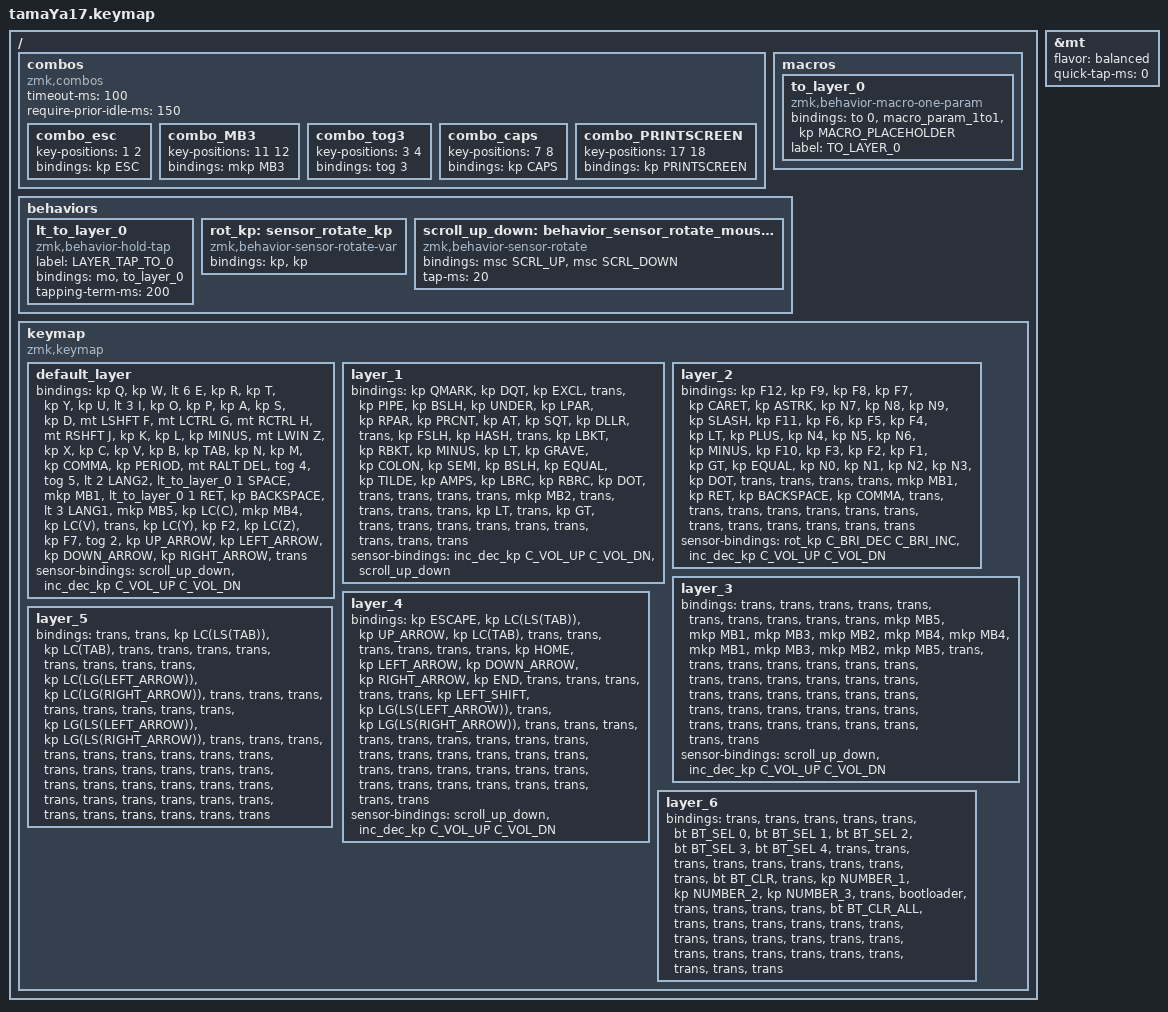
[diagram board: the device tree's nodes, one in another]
#include <behaviors.dtsi>
#include <dt-bindings/zmk/bt.h>
#include <dt-bindings/zmk/keys.h>
#include <dt-bindings/zmk/pointing.h>
#include <dt-bindings/zmk/mouse.h>
#include <behaviors/rgbled_widget.dtsi>  // led制御

#define ZMK_POINTING_DEFAULT_SCRL_VAL 100

#define MOUSE 3

&mt {
    flavor = "balanced";
    quick-tap-ms = <0>;
};

/ {
    // 複数キーの同時押しに特別の入力を設定できる
    // キー番号早見表：
    //  0  1  2  3  4         5  6  7  8  9
    // 10 11 12 13 14        15 16 17 18 19
    // 20 21 22 23 24        25 26 27 28 29
    

    combos {
        compatible = "zmk,combos";
        timeout-ms = <100>;
        require-prior-idle-ms = <150>;

        combo_esc {
            key-positions = <1 2>;
            bindings = <&kp  ESC>;
        };

        combo_MB3 {
            key-positions = <11 12>;
            bindings = <&mkp MB3>;
         };
    
        combo_tog3 {
            key-positions = <3 4>;
            bindings = <&tog 3>;
        };

        combo_caps {
            key-positions = <7 8>;
            bindings = <&kp CAPS>;
        };

        combo_PRINTSCREEN {
            key-positions = <17 18>;
            bindings = <&kp PRINTSCREEN>;
        };
       

    };

    //マクロ(既存のキーの組み合わせ)
    macros {
        to_layer_0: to_layer_0 {
            compatible = "zmk,behavior-macro-one-param";
            #binding-cells = <1>;
            bindings = <&to 0 &macro_param_1to1 &kp MACRO_PLACEHOLDER>;
            label = "TO_LAYER_0";
        };
    };

    //新たな動作を定義する
    behaviors {
        lt_to_layer_0: lt_to_layer_0 {
            compatible = "zmk,behavior-hold-tap";
            label = "LAYER_TAP_TO_0";
            bindings = <&mo>, <&to_layer_0>;

            #binding-cells = <2>;
            tapping-term-ms = <200>;
        };

        rot_kp: sensor_rotate_kp {
            compatible = "zmk,behavior-sensor-rotate-var";
            #sensor-binding-cells = <2>;
            bindings = <&kp>, <&kp>;
        };


        scroll_up_down: behavior_sensor_rotate_mouse_wheel_up_down {
            compatible = "zmk,behavior-sensor-rotate";
            #sensor-binding-cells = <0>;
            bindings = <&msc SCRL_UP>, <&msc SCRL_DOWN>;

            tap-ms = <20>;
        };

    };

    //キーマップ設定
    keymap {
        compatible = "zmk,keymap";

        default_layer { //デフォルトレイヤー(レイヤー0)
            bindings = <
            &kp Q       &kp W      &lt 6 E      &kp R         &kp T                                                      &kp Y           &kp U          &lt 3 I         &kp O           &kp P
            &kp A       &kp S      &kp D        &mt LSHFT F   &mt LCTRL G                                                &mt RCTRL H     &mt RSHFT J    &kp K           &kp L           &kp MINUS
            &mt LWIN Z  &kp X      &kp C        &kp V         &kp B                                &kp TAB               &kp N           &kp M          &kp COMMA       &kp PERIOD      &mt RALT DEL
                        &tog 4     &tog 5       &lt 2 LANG2   &lt_to_layer_0 1 SPACE  &mkp MB1     &lt_to_layer_0 1 RET  &kp BACKSPACE   &lt 3 LANG1                                
            &mkp MB5    &kp LC(C)  &mkp MB4     &kp LC(V)     &trans                                                     &kp LC(Y)       &kp F2         &kp LC(Z)       &kp F7          &tog 2
                                                                                                                         &kp UP_ARROW  &kp LEFT_ARROW   &kp DOWN_ARROW  &kp RIGHT_ARROW &trans
            >;

            sensor-bindings = 
                <&scroll_up_down>,
                <&inc_dec_kp C_VOL_UP C_VOL_DN>;
        };

        layer_1 {   //レイヤー1の時の設定
            bindings = <
            &kp QMARK  &kp DQT   &kp EXCL  &trans   &kp PIPE                           &kp BSLH  &kp UNDER  &kp LPAR  &kp RPAR  &kp PRCNT
            &kp AT     &kp SQT   &kp DLLR  &trans   &kp FSLH                           &kp HASH  &trans     &kp LBKT  &kp RBKT  &kp MINUS
            &kp LT     &kp GRAVE &kp COLON &kp SEMI &kp BSLH                &kp EQUAL  &kp TILDE &kp AMPS   &kp LBRC  &kp RBRC  &kp DOT
                       &trans    &trans    &trans   &trans    &mkp MB2      &trans     &trans    &trans
            &trans     &kp LT    &trans    &kp GT                                      &trans    &trans     &trans    &trans    &trans    
                                                                                       &trans    &trans     &trans    &trans
            >;

            sensor-bindings =
                <&inc_dec_kp C_VOL_UP C_VOL_DN>,
                <&scroll_up_down>;
        };

        layer_2 {   //レイヤー2の時の設定
            bindings = <
            &kp F12  &kp F9  &kp F8  &kp F7  &kp CARET                       &kp ASTRK     &kp N7  &kp N8  &kp N9  &kp SLASH
            &kp F11  &kp F6  &kp F5  &kp F4  &kp LT                          &kp PLUS      &kp N4  &kp N5  &kp N6  &kp MINUS
            &kp F10  &kp F3  &kp F2  &kp F1  &kp GT               &kp EQUAL  &kp N0        &kp N1  &kp N2  &kp N3  &kp DOT
                     &trans  &trans  &trans  &trans    &mkp MB1   &kp RET    &kp BACKSPACE &kp COMMA
            &trans   &trans  &trans  &trans                                  &trans        &trans  &trans  &trans  &trans    
                                                                             &trans        &trans  &trans  &trans
            >;

            sensor-bindings =
                <&rot_kp C_BRI_DEC C_BRI_INC>,
                <&inc_dec_kp C_VOL_UP C_VOL_DN>;
        };

        layer_3 {     //レイヤー3の時の設定(マウスレイヤー)
            bindings = <
            &trans    &trans    &trans    &trans    &trans                      &trans    &trans    &trans    &trans    &trans
            &mkp MB5  &mkp MB1  &mkp MB3  &mkp MB2  &mkp MB4                    &mkp MB4  &mkp MB1  &mkp MB3  &mkp MB2  &mkp MB5
            &trans    &trans    &trans    &trans    &trans              &trans  &trans    &trans    &trans    &trans    &trans
                      &trans    &trans    &trans    &trans    &trans    &trans  &trans    &trans
            &trans    &trans    &trans    &trans    &trans                      &trans    &trans    &trans    &trans    &trans
                                                                                &trans    &trans    &trans    &trans    
            >;

           sensor-bindings =
                <&scroll_up_down>,
                <&inc_dec_kp C_VOL_UP C_VOL_DN>;
            
        };


        layer_4 {    //レイヤー4の時の設定(DAWレイヤー)
            bindings = <
            &kp ESCAPE      &kp LC(LS(TAB))         &kp UP_ARROW    &kp LC(TAB)              &trans                         &trans  &trans  &trans  &trans  &trans
            &kp HOME        &kp LEFT_ARROW          &kp DOWN_ARROW  &kp RIGHT_ARROW          &kp END                        &trans  &trans  &trans  &trans  &trans
            &kp LEFT_SHIFT  &kp LG(LS(LEFT_ARROW))  &trans          &kp LG(LS(RIGHT_ARROW))  &trans                 &trans  &trans  &trans  &trans  &trans  &trans
                            &trans                  &trans          &trans                   &trans   &trans        &trans  &trans  &trans  
            &trans          &trans                  &trans          &trans                   &trans                         &trans  &trans  &trans  &trans  &trans    
                                                                                                                            &trans  &trans  &trans  &trans
            >;

            sensor-bindings = 
                <&scroll_up_down>,
                <&inc_dec_kp C_VOL_UP C_VOL_DN>;
        };

        layer_5 {   //レイヤー5の時の設定(3DCADレイヤー)
            bindings = <
            &trans  &trans  &kp LC(LS(TAB))         &kp LC(TAB)              &trans                     &trans  &trans  &trans  &trans  &trans
            &trans  &trans  &kp LC(LG(LEFT_ARROW))  &kp LC(LG(RIGHT_ARROW))  &trans                     &trans  &trans  &trans  &trans  &trans
            &trans  &trans  &kp LG(LS(LEFT_ARROW))  &kp LG(LS(RIGHT_ARROW))  &trans              &trans &trans  &trans  &trans  &trans  &trans
                    &trans  &trans                  &trans                   &trans   &trans     &trans &trans  &trans
            &trans  &trans  &trans                  &trans                                              &trans  &trans  &trans  &trans  &trans    
                                                                                                        &trans  &trans  &trans  &trans                                                                                      &trans  &trans  &trans  &trans  &trans
            >;

        };

        layer_6 {   //レイヤー6の時の設定
            bindings = <
            &trans  &trans        &trans        &trans        &trans                         &bt BT_SEL 0  &bt BT_SEL 1  &bt BT_SEL 2  &bt BT_SEL 3  &bt BT_SEL 4
            &trans  &trans        &trans        &trans        &trans                         &trans        &trans        &trans        &trans        &bt BT_CLR
            &trans  &kp NUMBER_1  &kp NUMBER_2  &kp NUMBER_3  &trans            &bootloader  &trans        &trans        &trans        &trans        &bt BT_CLR_ALL
                    &trans        &trans        &trans        &trans  &trans    &trans       &trans        &trans 
            &trans  &trans        &trans        &trans                                       &trans        &trans        &trans        &trans        &trans
                                                                                             &trans        &trans        &trans        &trans        
            >;
            
        };

        
    };
};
